# UART_1 register map
Vendor: Texas Instruments
Peripheral module from a debugger description file (folder msp430).
Registers are 8-bit, access not given, no defined reset value unless marked. A register's access mark holds for its fields unless they carry their own. Offsets are as the file gives them; lines under a group give offsets from that group; [hi:lo] are bit positions; {n}, {i} and the like mark numbered series; 'fields as' and 'values as' point back to an identical list; <NAME> marks a mode.

## UART
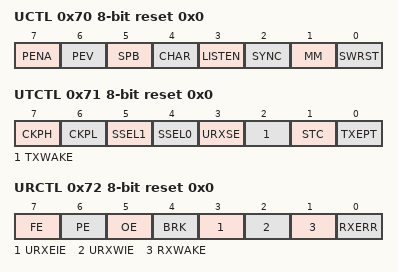
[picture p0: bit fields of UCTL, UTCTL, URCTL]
0x70 UCTL rw reset 0x0 — USART Control
  [7] PENA — UCTL
  [6] PEV
  [5] SPB — to distinguish from stackpointer SP
  [4] CHAR
  [3] LISTEN
  [2] SYNC
  [1] MM
  [0] SWRST
0x71 UTCTL rw reset 0x0 — USART Transmit Control
  [7] CKPH — UTCTL
  [6] CKPL
  [5] SSEL1
  [4] SSEL0
  [3] URXSE
  [2] TXWAKE
  [1] STC
  [0] TXEPT
0x72 URCTL rw reset 0x0 — USART Receive Control
  [7] FE — URCTL
  [6] PE
  [5] OE
  [4] BRK
  [3] URXEIE
  [2] URXWIE
  [1] RXWAKE
  [0] RXERR
0x73 UMCTL — USART Modulation Control
0x74 UBR0 — USART Baud Rate 0
0x75 UBR1 — USART Buad Rate 1
0x76 RXBUF — USART Receive Buffer
0x77 TXBUF — USART Transmit Buffer
